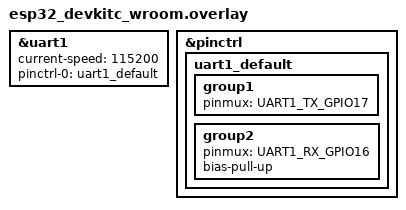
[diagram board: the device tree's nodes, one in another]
/*
 * ESP32-DevKitC-WROOM Devicetree Overlay for Orion B16 GNSS
 *
 * WHAT THIS DOES:
 *   Enables UART1 on your ESP32 so the Orion B16 driver can talk to
 *   the GNSS chip (or to nothing / a loopback wire while testing).
 *
 *   UART0 = your USB serial console (for LOG_INF prints, etc.)
 *   UART1 = connected to the Orion B16 (or test wires)
 *
 * PIN WIRING (ESP32 → Orion B16):
 *   ESP32 GPIO 17  (TX out) ──→  Orion RX pin
 *   ESP32 GPIO 16  (RX in)  ←──  Orion TX pin
 *   ESP32 GND      ──────────→  Orion GND
 *
 * If you don't have the Orion B16 hardware yet, that's fine!
 * The app will just print "No valid fix yet" every 5 seconds.
 * You can also jumper GPIO17 → GPIO16 for a loopback self-test.
 */

/*
 * Enable UART1 and set baud rate to 115200 (Orion B16 default).
 * The pin mapping (GPIO17=TX, GPIO16=RX) is set below in &pinctrl.
 */
&uart1 {
	status = "okay";
	current-speed = <115200>;
	pinctrl-0 = <&uart1_default>;
	pinctrl-names = "default";
};

/*
 * Pin Control: map UART1 signals to physical GPIO pins.
 * UART1_TX_GPIO17 and UART1_RX_GPIO16 are macros from Zephyr's
 * ESP32 pinctrl headers — they configure the internal mux.
 */
&pinctrl {
	uart1_default: uart1_default {
		group1 {
			pinmux = <UART1_TX_GPIO17>;
		};
		group2 {
			pinmux = <UART1_RX_GPIO16>;
			bias-pull-up;
		};
	};
};
